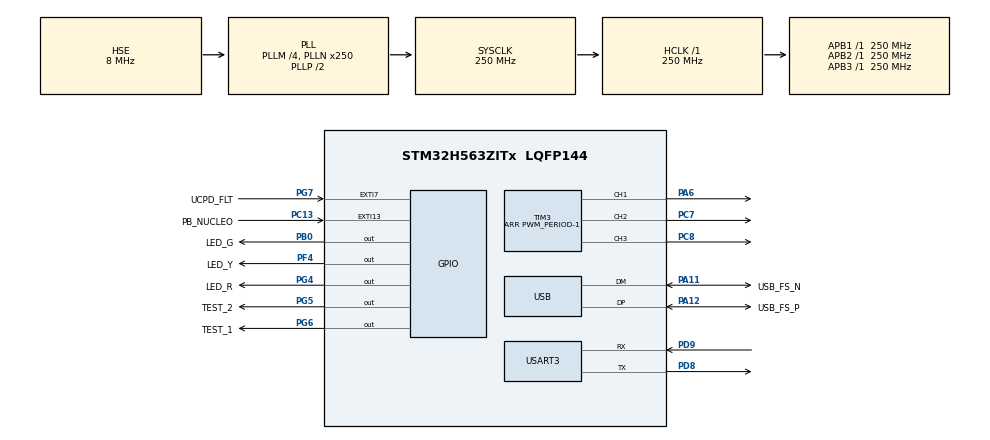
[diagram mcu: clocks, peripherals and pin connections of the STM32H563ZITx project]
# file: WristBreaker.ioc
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BOOTPATH.BootPathName=LEGACY
BOOTPATH.UserSelectedBootPath=LEGACY
CORTEX_M33_NS.userName=CORTEX_M33
Mcu.Family=STM32H5
Mcu.Name=STM32H563ZITx
Mcu.Package=LQFP144
Mcu.UserConstants=PWM_PERIOD,6250
NVIC.PriorityGroup=NVIC_PRIORITYGROUP_4
NVIC.TIM6_IRQn=true\:15\:0\:false\:false\:true\:false\:false\:true\:true
NVIC.TimeBase=TIM6_IRQn
NVIC.TimeBaseIP=TIM6
NVIC.USB_DRD_FS_IRQn=true\:0\:0\:false\:false\:true\:false\:true\:true\:true
PA1.GPIO_Label=RMII_REF_CLK
PA1.GPIO_Mode=GPIO_MODE_AF_PP
PA1.GPIO_PuPd=GPIO_NOPULL
PA1.GPIO_Speed=GPIO_SPEED_FREQ_LOW
PA1.Signal=ETH_REF_CLK
PA11.GPIO_Label=USB_FS_N
PA11.Mode=Device
PA11.Signal=USB_DM
PA12.GPIO_Label=USB_FS_P
PA12.Mode=Device
PA12.Signal=USB_DP
PA13(JTMS/SWDIO).GPIO_Label=SWDIO
PA13(JTMS/SWDIO).Signal=DEBUG_JTMS-SWDIO
PA14(JTCK/SWCLK).GPIO_Label=SWCLK
PA14(JTCK/SWCLK).Signal=DEBUG_JTCK-SWCLK
PA15(JTDI).GPIO_Label=T_JTDI
PA15(JTDI).Signal=DEBUG_JTDI
PA2.GPIO_Label=RMII_MDIO
PA2.GPIO_Mode=GPIO_MODE_AF_PP
PA2.GPIO_PuPd=GPIO_NOPULL
PA2.GPIO_Speed=GPIO_SPEED_FREQ_LOW
PA2.Signal=ETH_MDIO
PA4.GPIO_Label=VBUS_SENSE
PA4.Signal=ADCx_INP18
PA6.Signal=S_TIM3_CH1
PA7.GPIO_Label=RMII_CRS_DV
PA7.GPIO_Mode=GPIO_MODE_AF_PP
PA7.GPIO_PuPd=GPIO_NOPULL
PA7.GPIO_Speed=GPIO_SPEED_FREQ_LOW
PA7.Signal=ETH_CRS_DV
PA9.GPIO_Label=UCDP_DBn
PA9.Signal=UCPD1_DB1
PB0.GPIO_Label=LED_G
PB0.Signal=GPIO_Output
PB13.GPIO_Label=UCPD_CC1
PB13.Signal=UCPD1_CC1
PB14.GPIO_Label=UCPD_CC2
PB14.Signal=UCPD1_CC2
PB15.GPIO_Label=RMII_TXD1
PB15.GPIO_Mode=GPIO_MODE_AF_PP
PB15.GPIO_PuPd=GPIO_NOPULL
PB15.GPIO_Speed=GPIO_SPEED_FREQ_LOW
PB15.Signal=ETH_TXD1
PB3(JTDO/TRACESWO).GPIO_Label=SWO
PB3(JTDO/TRACESWO).Signal=DEBUG_JTDO-SWO
PB6.GPIO_Label=ARD_D1_TX
PB6.Signal=LPUART1_TX
PB7.GPIO_Label=ARD_D0_RX
PB7.Signal=LPUART1_RX
PC1.GPIO_Label=RMII_MDC
PC1.GPIO_Mode=GPIO_MODE_AF_PP
PC1.GPIO_PuPd=GPIO_NOPULL
PC1.GPIO_Speed=GPIO_SPEED_FREQ_LOW
PC1.Signal=ETH_MDC
PC13.GPIO_Label=PB_NUCLEO
PC13.Signal=GPXTI13
PC14-OSC32_IN(OSC32_IN).Mode=LSE-External-Oscillator
PC14-OSC32_IN(OSC32_IN).Signal=RCC_OSC32_IN
PC15-OSC32_OUT(OSC32_OUT).Mode=LSE-External-Oscillator
PC15-OSC32_OUT(OSC32_OUT).Signal=RCC_OSC32_OUT
PC4.GPIO_Label=RMII_RXD0
PC4.GPIO_Mode=GPIO_MODE_AF_PP
PC4.GPIO_PuPd=GPIO_NOPULL
PC4.GPIO_Speed=GPIO_SPEED_FREQ_LOW
PC4.Signal=ETH_RXD0
PC5.GPIO_Label=RMII_RXD1
PC5.GPIO_Mode=GPIO_MODE_AF_PP
PC5.GPIO_PuPd=GPIO_NOPULL
PC5.GPIO_Speed=GPIO_SPEED_FREQ_LOW
PC5.Signal=ETH_RXD1
PC7.Signal=S_TIM3_CH2
PC8.Signal=S_TIM3_CH3
PD8.Mode=Asynchronous
PD8.Signal=USART3_TX
PD9.Mode=Asynchronous
PD9.Signal=USART3_RX
PE2.GPIO_Label=TRACE_CK
PE2.Signal=DEBUG_TRACECLK
PE3.GPIO_Label=TRACE_D0
PE3.Signal=DEBUG_TRACED0
PE4.GPIO_Label=TRACE_D1
PE4.Signal=DEBUG_TRACED1
PE5.GPIO_Label=TRACE_D2
PE5.Signal=DEBUG_TRACED2
PE6.GPIO_Label=TRACE_D3
PE6.Signal=DEBUG_TRACED3
PF4.GPIO_Label=LED_Y
PF4.Signal=GPIO_Output
PG11.GPIO_Label=RMII_TXT_EN
PG11.GPIO_Mode=GPIO_MODE_AF_PP
PG11.GPIO_PuPd=GPIO_NOPULL
PG11.GPIO_Speed=GPIO_SPEED_FREQ_LOW
PG11.Signal=ETH_TX_EN
PG13.GPIO_Label=RMI_TXD0
PG13.GPIO_Mode=GPIO_MODE_AF_PP
PG13.GPIO_PuPd=GPIO_NOPULL
PG13.GPIO_Speed=GPIO_SPEED_FREQ_LOW
PG13.Signal=ETH_TXD0
PG4.GPIO_Label=LED_R
PG4.Signal=GPIO_Output
PG5.GPIO_Label=TEST_2
PG5.GPIO_Speed=GPIO_SPEED_FREQ_MEDIUM
PG5.Signal=GPIO_Output
PG6.GPIO_Label=TEST_1
PG6.GPIO_Speed=GPIO_SPEED_FREQ_MEDIUM
PG6.Signal=GPIO_Output
PG7.GPIO_Label=UCPD_FLT
PG7.Signal=GPXTI7
PH0-OSC_IN(PH0).GPIO_Label=STLK_MCO
PH0-OSC_IN(PH0).Mode=HSE-External-Clock-Source
PH0-OSC_IN(PH0).Signal=RCC_OSC_IN
ProjectManager.HeapSize=0x200
ProjectManager.StackSize=0x400
ProjectManager.TargetToolchain=CMake
RCC.ADCFreq_Value=250000000
RCC.AHBFreq_Value=250000000
RCC.APB1Freq_Value=250000000
RCC.APB1TimFreq_Value=250000000
RCC.APB2Freq_Value=250000000
RCC.APB2TimFreq_Value=250000000
RCC.APB3Freq_Value=250000000
RCC.CSI_VALUE=4000000
RCC.CortexFreq_Value=250000000
RCC.EPOD_VALUE=8000000
RCC.HCLKFreq_Value=250000000
RCC.HSE_VALUE=8000000
RCC.HSI48_VALUE=48000000
RCC.HSIDiv=RCC_HSI_DIV1
RCC.HSI_VALUE=64000000
RCC.LSIRC_VALUE=32000
RCC.PLLM=4
RCC.PLLN=250
RCC.PLLSourceVirtual=RCC_PLL1_SOURCE_HSE
RCC.SYSCLKFreq_VALUE=250000000
RCC.SYSCLKSource=RCC_SYSCLKSOURCE_PLLCLK
RCC.USBFreq_Value=48000000
RCC.VCOOutputFreq_Value=500000000
SH.ADCx_INP18.0=ADC1_INP18
SH.S_TIM3_CH1.0=TIM3_CH1,PWM Generation1 CH1
SH.S_TIM3_CH2.0=TIM3_CH2,PWM Generation2 CH2
SH.S_TIM3_CH3.0=TIM3_CH3,PWM Generation3 CH3
TIM3.Channel-PWM\ Generation1\ CH1=TIM_CHANNEL_1
TIM3.Channel-PWM\ Generation2\ CH2=TIM_CHANNEL_2
TIM3.Channel-PWM\ Generation3\ CH3=TIM_CHANNEL_3
TIM3.CounterMode=TIM_COUNTERMODE_CENTERALIGNED1
TIM3.PeriodNoDither=PWM_PERIOD-1
TIM3.PulseNoDither_1=1
TIM3.PulseNoDither_2=1
TIM3.PulseNoDither_3=1
USART3.VirtualMode-Asynchronous=VM_ASYNC
USB.VirtualMode=Device_Only
USBX.BSP.number=1
USBX.Core_System=1
USBX.USBD_HID_CUSTOM_EPIN_FS_BINTERVAL=1
USBX.USBD_HID_CUSTOM_EPIN_HS_BINTERVAL=1
USBX.USBD_HID_CUSTOM_EPOUT_ADDR=1
USBX.USBD_HID_CUSTOM_EPOUT_FS_BINTERVAL=1
USBX.USBD_HID_CUSTOM_EPOUT_HS_BINTERVAL=1
USBX.USBD_MANUFACTURER_STRING=MS Controllers
USBX.USBD_PID=22369
USBX.USBD_PRODUCT_STRING=WristBreaker
USBX.USBX_DEVICE_SYS_SIZE=8*1024
USBX.UX_DEVICE_APP_MEM_POOL_SIZE=16*1024
USBX.UX_DEVICE_CLASS_HID_INTERRUPT_OUT_SUPPORT=1
USBX.UX_DEVICE_HID_CORE=1
USBX.UX_DEVICE_HID_CUSTOM=1
USBX.UX_Device_Controller=1
USBX.UX_Device_CoreStack=1
USBX.UX_SLAVE_REQUEST_DATA_MAX_LENGTH=512
USBX0.BSP.STBoard=false
USBX0.BSP.api=Unknown
USBX0.BSP.instance=USB
USBX0.BSP.ip=USB
USBX0.BSP.mode=Device_Only
USBX0.BSP.name=USB_Device
USBX0.BSP.solution=USB
VP_BOOTPATH_VS_BOOTPATH.Mode=BP_Activate
VP_CORTEX_M33_NS_VS_Hclk.Mode=Hclk_Mode
VP_ICACHE_VS_ENABLE_ICACHE_MEMORY.Mode=Memoryregions
VP_ICACHE_VS_ICACHE.Mode=DefaultMode
VP_MEMORYMAP_VS_MEMORYMAP.Mode=CurAppReg
VP_PWR_VS_DBSignals.Mode=DisableDeadBatterySignals
VP_PWR_VS_LPOM.Mode=PowerOptimisation
VP_PWR_VS_SECSignals.Mode=Security/Privilege
VP_RCC_USB.Mode=CRS SYNC Source USB
VP_SYS_VS_tim6.Mode=TIM6
VP_THREADX_VS_RTOSJjThreadXJjCoreJjDefault.Mode=Core_Default
VP_TIM3_VS_ClockSourceINT.Mode=Internal
VP_USBX_Core_System.Mode=Core_System
VP_USBX_UX\ Device\ Controller_FS.Mode=UX_Device_Controller_FS
VP_USBX_UX\ Device\ CoreStack_FS.Mode=UX_Device_CoreStack_FS
VP_USBX_UX\ Device\ HID_CORE_FS.Mode=UX_Device_class_HID_CORE_FS
VP_USBX_UX\ Device\ HID_CUSTOM_FS.Mode=UX_Device_class_HID_CUSTOM_FS
board=NUCLEO-H563ZI

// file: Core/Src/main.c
/* USER CODE BEGIN Header */
/**
  ******************************************************************************
  * @file           : main.c
  * @brief          : Main program body
  ******************************************************************************
  * @attention
  *
  * Copyright (c) 2024 STMicroelectronics.
  * All rights reserved.
  *
  * This software is licensed under terms that can be found in the LICENSE file
  * in the root directory of this software component.
  * If no LICENSE file comes with this software, it is provided AS-IS.
  *
  ******************************************************************************
  */
/* USER CODE END Header */
#include "app_threadx.h"
#include "main.h"
#include "game_controller.h"

/* USER CODE BEGIN Includes */
#include "logger.h"
/* USER CODE END Includes */

TIM_HandleTypeDef htim3;

UART_HandleTypeDef huart3;

PCD_HandleTypeDef hpcd_USB_DRD_FS;

void SystemClock_Config(void);
static void MX_GPIO_Init(void);
static void MX_ICACHE_Init(void);
static void MX_USART3_UART_Init(void);
static void MX_TIM3_Init(void);

int main(void)
{

  /* MCU Configuration--------------------------------------------------------*/

  /* Reset of all peripherals, Initializes the Flash interface and the Systick. */
  HAL_Init();

  /* Configure the system clock */
  SystemClock_Config();

  /* Initialize all configured peripherals */
  MX_GPIO_Init();
  MX_ICACHE_Init();
  MX_USART3_UART_Init();
  MX_TIM3_Init();
  /* USER CODE BEGIN 2 */
  pLoggerUART = &huart3;
  pMotor_X_Timer = &htim3;

  LOG_INFO("WristBreaker H5 ver 0.1");

  /* USER CODE END 2 */

  MX_ThreadX_Init();

  /* We should never get here as control is now taken by the scheduler */

  /* Infinite loop */
  while (1)
  {

  }
}

void SystemClock_Config(void)
{
  RCC_OscInitTypeDef RCC_OscInitStruct = {0};
  RCC_ClkInitTypeDef RCC_ClkInitStruct = {0};
  RCC_CRSInitTypeDef RCC_CRSInitStruct = {0};

  /** Configure the main internal regulator output voltage
  */
  __HAL_PWR_VOLTAGESCALING_CONFIG(PWR_REGULATOR_VOLTAGE_SCALE0);

  while(!__HAL_PWR_GET_FLAG(PWR_FLAG_VOSRDY)) {}

  /** Initializes the RCC Oscillators according to the specified parameters
  * in the RCC_OscInitTypeDef structure.
  */
  RCC_OscInitStruct.OscillatorType = RCC_OSCILLATORTYPE_HSI48|RCC_OSCILLATORTYPE_HSE;
  RCC_OscInitStruct.HSEState = RCC_HSE_BYPASS;
  RCC_OscInitStruct.HSI48State = RCC_HSI48_ON;
  RCC_OscInitStruct.PLL.PLLState = RCC_PLL_ON;
  RCC_OscInitStruct.PLL.PLLSource = RCC_PLL1_SOURCE_HSE;
  RCC_OscInitStruct.PLL.PLLM = 4;
  RCC_OscInitStruct.PLL.PLLN = 250;
  RCC_OscInitStruct.PLL.PLLP = 2;
  RCC_OscInitStruct.PLL.PLLQ = 2;
  RCC_OscInitStruct.PLL.PLLR = 2;
  RCC_OscInitStruct.PLL.PLLRGE = RCC_PLL1_VCIRANGE_1;
  RCC_OscInitStruct.PLL.PLLVCOSEL = RCC_PLL1_VCORANGE_WIDE;
  RCC_OscInitStruct.PLL.PLLFRACN = 0;
  if (HAL_RCC_OscConfig(&RCC_OscInitStruct) != HAL_OK)
  {
    Error_Handler();
  }

  /** Initializes the CPU, AHB and APB buses clocks
  */
  RCC_ClkInitStruct.ClockType = RCC_CLOCKTYPE_HCLK|RCC_CLOCKTYPE_SYSCLK
                              |RCC_CLOCKTYPE_PCLK1|RCC_CLOCKTYPE_PCLK2
                              |RCC_CLOCKTYPE_PCLK3;
  RCC_ClkInitStruct.SYSCLKSource = RCC_SYSCLKSOURCE_PLLCLK;
  RCC_ClkInitStruct.AHBCLKDivider = RCC_SYSCLK_DIV1;
  RCC_ClkInitStruct.APB1CLKDivider = RCC_HCLK_DIV1;
  RCC_ClkInitStruct.APB2CLKDivider = RCC_HCLK_DIV1;
  RCC_ClkInitStruct.APB3CLKDivider = RCC_HCLK_DIV1;

  if (HAL_RCC_ClockConfig(&RCC_ClkInitStruct, FLASH_LATENCY_5) != HAL_OK)
  {
    Error_Handler();
  }

  /** Enable the CRS APB clock
  */
  __HAL_RCC_CRS_CLK_ENABLE();

  /** Configures CRS
  */
  RCC_CRSInitStruct.Prescaler = RCC_CRS_SYNC_DIV1;
  RCC_CRSInitStruct.Source = RCC_CRS_SYNC_SOURCE_USB;
  RCC_CRSInitStruct.Polarity = RCC_CRS_SYNC_POLARITY_RISING;
  RCC_CRSInitStruct.ReloadValue = __HAL_RCC_CRS_RELOADVALUE_CALCULATE(48000000,1000);
  RCC_CRSInitStruct.ErrorLimitValue = 34;
  RCC_CRSInitStruct.HSI48CalibrationValue = 32;

  HAL_RCCEx_CRSConfig(&RCC_CRSInitStruct);

  /** Configure the programming delay
  */
  __HAL_FLASH_SET_PROGRAM_DELAY(FLASH_PROGRAMMING_DELAY_2);
}

static void MX_ICACHE_Init(void)
{

  /** Enable instruction cache (default 2-ways set associative cache)
  */
  if (HAL_ICACHE_Enable() != HAL_OK)
  {
    Error_Handler();
  }

}

static void MX_TIM3_Init(void)
{

  TIM_ClockConfigTypeDef sClockSourceConfig = {0};
  TIM_MasterConfigTypeDef sMasterConfig = {0};
  TIM_OC_InitTypeDef sConfigOC = {0};

  htim3.Instance = TIM3;
  htim3.Init.Prescaler = 0;
  htim3.Init.CounterMode = TIM_COUNTERMODE_CENTERALIGNED1;
  htim3.Init.Period = 6249;
  htim3.Init.ClockDivision = TIM_CLOCKDIVISION_DIV1;
  htim3.Init.AutoReloadPreload = TIM_AUTORELOAD_PRELOAD_DISABLE;
  if (HAL_TIM_Base_Init(&htim3) != HAL_OK)
  {
    Error_Handler();
  }
  sClockSourceConfig.ClockSource = TIM_CLOCKSOURCE_INTERNAL;
  if (HAL_TIM_ConfigClockSource(&htim3, &sClockSourceConfig) != HAL_OK)
  {
    Error_Handler();
  }
  if (HAL_TIM_PWM_Init(&htim3) != HAL_OK)
  {
    Error_Handler();
  }
  sMasterConfig.MasterOutputTrigger = TIM_TRGO_RESET;
  sMasterConfig.MasterSlaveMode = TIM_MASTERSLAVEMODE_DISABLE;
  if (HAL_TIMEx_MasterConfigSynchronization(&htim3, &sMasterConfig) != HAL_OK)
  {
    Error_Handler();
  }
  sConfigOC.OCMode = TIM_OCMODE_PWM1;
  sConfigOC.Pulse = 1;
  sConfigOC.OCPolarity = TIM_OCPOLARITY_HIGH;
  sConfigOC.OCFastMode = TIM_OCFAST_DISABLE;
  if (HAL_TIM_PWM_ConfigChannel(&htim3, &sConfigOC, TIM_CHANNEL_1) != HAL_OK)
  {
    Error_Handler();
  }
  if (HAL_TIM_PWM_ConfigChannel(&htim3, &sConfigOC, TIM_CHANNEL_2) != HAL_OK)
  {
    Error_Handler();
  }
  if (HAL_TIM_PWM_ConfigChannel(&htim3, &sConfigOC, TIM_CHANNEL_3) != HAL_OK)
  {
    Error_Handler();
  }
  HAL_TIM_MspPostInit(&htim3);

}

static void MX_USART3_UART_Init(void)
{

  huart3.Instance = USART3;
  huart3.Init.BaudRate = 115200;
  huart3.Init.WordLength = UART_WORDLENGTH_8B;
  huart3.Init.StopBits = UART_STOPBITS_1;
  huart3.Init.Parity = UART_PARITY_NONE;
  huart3.Init.Mode = UART_MODE_TX_RX;
  huart3.Init.HwFlowCtl = UART_HWCONTROL_NONE;
  huart3.Init.OverSampling = UART_OVERSAMPLING_16;
  huart3.Init.OneBitSampling = UART_ONE_BIT_SAMPLE_DISABLE;
  huart3.Init.ClockPrescaler = UART_PRESCALER_DIV1;
  huart3.AdvancedInit.AdvFeatureInit = UART_ADVFEATURE_NO_INIT;
  if (HAL_UART_Init(&huart3) != HAL_OK)
  {
    Error_Handler();
  }
  if (HAL_UARTEx_SetTxFifoThreshold(&huart3, UART_TXFIFO_THRESHOLD_1_8) != HAL_OK)
  {
    Error_Handler();
  }
  if (HAL_UARTEx_SetRxFifoThreshold(&huart3, UART_RXFIFO_THRESHOLD_1_8) != HAL_OK)
  {
    Error_Handler();
  }
  if (HAL_UARTEx_DisableFifoMode(&huart3) != HAL_OK)
  {
    Error_Handler();
  }

}

void MX_USB_PCD_Init(void)
{

  hpcd_USB_DRD_FS.Instance = USB_DRD_FS;
  hpcd_USB_DRD_FS.Init.dev_endpoints = 8;
  hpcd_USB_DRD_FS.Init.speed = USBD_FS_SPEED;
  hpcd_USB_DRD_FS.Init.phy_itface = PCD_PHY_EMBEDDED;
  hpcd_USB_DRD_FS.Init.Sof_enable = DISABLE;
  hpcd_USB_DRD_FS.Init.low_power_enable = DISABLE;
  hpcd_USB_DRD_FS.Init.lpm_enable = DISABLE;
  hpcd_USB_DRD_FS.Init.battery_charging_enable = DISABLE;
  hpcd_USB_DRD_FS.Init.vbus_sensing_enable = DISABLE;
  hpcd_USB_DRD_FS.Init.bulk_doublebuffer_enable = DISABLE;
  hpcd_USB_DRD_FS.Init.iso_singlebuffer_enable = DISABLE;
  if (HAL_PCD_Init(&hpcd_USB_DRD_FS) != HAL_OK)
  {
    Error_Handler();
  }
  /* USER CODE BEGIN USB_Init 2 */
  LOG_INFO("MX_USB_PCD_Init success");
  /* USER CODE END USB_Init 2 */

}

static void MX_GPIO_Init(void)
{
  GPIO_InitTypeDef GPIO_InitStruct = {0};

  /* GPIO Ports Clock Enable */
  __HAL_RCC_GPIOE_CLK_ENABLE();
  __HAL_RCC_GPIOC_CLK_ENABLE();
  __HAL_RCC_GPIOF_CLK_ENABLE();
  __HAL_RCC_GPIOH_CLK_ENABLE();
  __HAL_RCC_GPIOA_CLK_ENABLE();
  __HAL_RCC_GPIOB_CLK_ENABLE();
  __HAL_RCC_GPIOD_CLK_ENABLE();
  __HAL_RCC_GPIOG_CLK_ENABLE();

  /*Configure GPIO pin Output Level */
  HAL_GPIO_WritePin(LED_Y_GPIO_Port, LED_Y_Pin, GPIO_PIN_RESET);

  /*Configure GPIO pin Output Level */
  HAL_GPIO_WritePin(LED_G_GPIO_Port, LED_G_Pin, GPIO_PIN_RESET);

  /*Configure GPIO pin Output Level */
  HAL_GPIO_WritePin(GPIOG, LED_R_Pin|TEST_2_Pin|TEST_1_Pin, GPIO_PIN_RESET);

  /*Configure GPIO pin : PB_NUCLEO_Pin */
  GPIO_InitStruct.Pin = PB_NUCLEO_Pin;
  GPIO_InitStruct.Mode = GPIO_MODE_IT_RISING;
  GPIO_InitStruct.Pull = GPIO_NOPULL;
  HAL_GPIO_Init(PB_NUCLEO_GPIO_Port, &GPIO_InitStruct);

  /*Configure GPIO pin : LED_Y_Pin */
  GPIO_InitStruct.Pin = LED_Y_Pin;
  GPIO_InitStruct.Mode = GPIO_MODE_OUTPUT_PP;
  GPIO_InitStruct.Pull = GPIO_NOPULL;
  GPIO_InitStruct.Speed = GPIO_SPEED_FREQ_LOW;
  HAL_GPIO_Init(LED_Y_GPIO_Port, &GPIO_InitStruct);

  /*Configure GPIO pins : RMII_MDC_Pin RMII_RXD0_Pin RMII_RXD1_Pin */
  GPIO_InitStruct.Pin = RMII_MDC_Pin|RMII_RXD0_Pin|RMII_RXD1_Pin;
  GPIO_InitStruct.Mode = GPIO_MODE_AF_PP;
  GPIO_InitStruct.Pull = GPIO_NOPULL;
  GPIO_InitStruct.Speed = GPIO_SPEED_FREQ_HIGH;
  GPIO_InitStruct.Alternate = GPIO_AF11_ETH;
  HAL_GPIO_Init(GPIOC, &GPIO_InitStruct);

  /*Configure GPIO pins : RMII_REF_CLK_Pin RMII_MDIO_Pin RMII_CRS_DV_Pin */
  GPIO_InitStruct.Pin = RMII_REF_CLK_Pin|RMII_MDIO_Pin|RMII_CRS_DV_Pin;
  GPIO_InitStruct.Mode = GPIO_MODE_AF_PP;
  GPIO_InitStruct.Pull = GPIO_NOPULL;
  GPIO_InitStruct.Speed = GPIO_SPEED_FREQ_HIGH;
  GPIO_InitStruct.Alternate = GPIO_AF11_ETH;
  HAL_GPIO_Init(GPIOA, &GPIO_InitStruct);

  /*Configure GPIO pin : VBUS_SENSE_Pin */
  GPIO_InitStruct.Pin = VBUS_SENSE_Pin;
  GPIO_InitStruct.Mode = GPIO_MODE_ANALOG;
  GPIO_InitStruct.Pull = GPIO_NOPULL;
  HAL_GPIO_Init(VBUS_SENSE_GPIO_Port, &GPIO_InitStruct);

  /*Configure GPIO pin : LED_G_Pin */
  GPIO_InitStruct.Pin = LED_G_Pin;
  GPIO_InitStruct.Mode = GPIO_MODE_OUTPUT_PP;
  GPIO_InitStruct.Pull = GPIO_NOPULL;
  GPIO_InitStruct.Speed = GPIO_SPEED_FREQ_LOW;
  HAL_GPIO_Init(LED_G_GPIO_Port, &GPIO_InitStruct);

  /*Configure GPIO pins : UCPD_CC1_Pin UCPD_CC2_Pin */
  GPIO_InitStruct.Pin = UCPD_CC1_Pin|UCPD_CC2_Pin;
  GPIO_InitStruct.Mode = GPIO_MODE_ANALOG;
  GPIO_InitStruct.Pull = GPIO_NOPULL;
  HAL_GPIO_Init(GPIOB, &GPIO_InitStruct);

  /*Configure GPIO pin : RMII_TXD1_Pin */
  GPIO_InitStruct.Pin = RMII_TXD1_Pin;
  GPIO_InitStruct.Mode = GPIO_MODE_AF_PP;
  GPIO_InitStruct.Pull = GPIO_NOPULL;
  GPIO_InitStruct.Speed = GPIO_SPEED_FREQ_HIGH;
  GPIO_InitStruct.Alternate = GPIO_AF11_ETH;
  HAL_GPIO_Init(RMII_TXD1_GPIO_Port, &GPIO_InitStruct);

  /*Configure GPIO pin : LED_R_Pin */
  GPIO_InitStruct.Pin = LED_R_Pin;
  GPIO_InitStruct.Mode = GPIO_MODE_OUTPUT_PP;
  GPIO_InitStruct.Pull = GPIO_NOPULL;
  GPIO_InitStruct.Speed = GPIO_SPEED_FREQ_LOW;
  HAL_GPIO_Init(LED_R_GPIO_Port, &GPIO_InitStruct);

  /*Configure GPIO pins : TEST_2_Pin TEST_1_Pin */
  GPIO_InitStruct.Pin = TEST_2_Pin|TEST_1_Pin;
  GPIO_InitStruct.Mode = GPIO_MODE_OUTPUT_PP;
  GPIO_InitStruct.Pull = GPIO_NOPULL;
  GPIO_InitStruct.Speed = GPIO_SPEED_FREQ_MEDIUM;
  HAL_GPIO_Init(GPIOG, &GPIO_InitStruct);

  /*Configure GPIO pin : UCPD_FLT_Pin */
  GPIO_InitStruct.Pin = UCPD_FLT_Pin;
  GPIO_InitStruct.Mode = GPIO_MODE_IT_RISING;
  GPIO_InitStruct.Pull = GPIO_NOPULL;
  HAL_GPIO_Init(UCPD_FLT_GPIO_Port, &GPIO_InitStruct);

  /*Configure GPIO pins : RMII_TXT_EN_Pin RMI_TXD0_Pin */
  GPIO_InitStruct.Pin = RMII_TXT_EN_Pin|RMI_TXD0_Pin;
  GPIO_InitStruct.Mode = GPIO_MODE_AF_PP;
  GPIO_InitStruct.Pull = GPIO_NOPULL;
  GPIO_InitStruct.Speed = GPIO_SPEED_FREQ_HIGH;
  GPIO_InitStruct.Alternate = GPIO_AF11_ETH;
  HAL_GPIO_Init(GPIOG, &GPIO_InitStruct);

  /*Configure GPIO pins : ARD_D1_TX_Pin ARD_D0_RX_Pin */
  GPIO_InitStruct.Pin = ARD_D1_TX_Pin|ARD_D0_RX_Pin;
  GPIO_InitStruct.Mode = GPIO_MODE_AF_PP;
  GPIO_InitStruct.Pull = GPIO_NOPULL;
  GPIO_InitStruct.Speed = GPIO_SPEED_FREQ_LOW;
  GPIO_InitStruct.Alternate = GPIO_AF8_LPUART1;
  HAL_GPIO_Init(GPIOB, &GPIO_InitStruct);

}

void HAL_TIM_PeriodElapsedCallback(TIM_HandleTypeDef *htim)
{
  if (htim->Instance == TIM6) {
    HAL_IncTick();
  }
}

void Error_Handler(void)
{
  /* USER CODE BEGIN Error_Handler_Debug */
  /* User can add his own implementation to report the HAL error return state */
  __disable_irq();
  HAL_GPIO_WritePin(LED_R_GPIO_Port, LED_R_Pin, GPIO_PIN_SET);
  while (1)
  {
  }
  /* USER CODE END Error_Handler_Debug */
}
